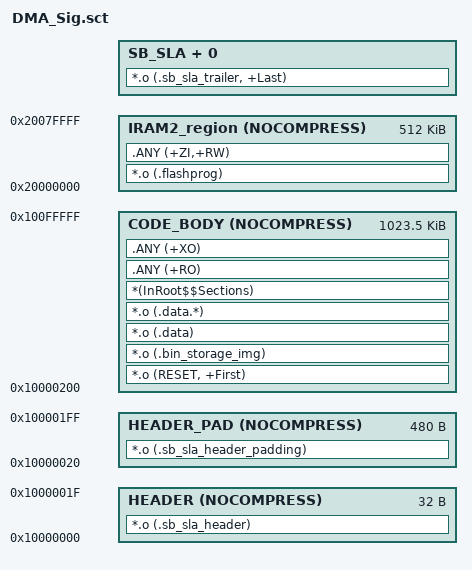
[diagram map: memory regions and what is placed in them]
#! armclang -E --target=arm-arm-none-eabi -mcpu=cortex-m4 -x c


; *************************************************************
; *** Scatter-Loading Description File generated by uVision ***
; *************************************************************

; /*-Memory Regions-*/
#define ROM_start         0x00000000
#define ROM_size          0x00020000
#define FLASH_start__     0x10000000
#define FLASH_size__      0x00100000
#define HEADER_start__    0x10000000
#define HEADER_size__     0x00000020
#define HEADERpad_start__ 0x10000020
#define HEADERpad_size__  0x000001E0
#define CODE_start__      0x10000200
#define CODE_size__       0x000FFE00
#define SPIX_start__      0x08000000
#define SPIX_size__       0x05A12000
#define IRAM_start__      0x20000000
#define IRAM_size__       0x00080000  


LR_IROM1 FLASH_start__ FLASH_size__ { ; load region size_region

	HEADER HEADER_start__  NOCOMPRESS  HEADER_size__ {
		*.o (.sb_sla_header)
	}

	HEADER_PAD HEADERpad_start__  NOCOMPRESS  HEADERpad_size__ {
		*.o (.sb_sla_header_padding)
	}

	CODE_BODY CODE_start__  NOCOMPRESS  CODE_size__ {
		*.o (RESET, +First)
		*.o (.bin_storage_img)
		*.o (.data)
        *.o (.data.*)        
		*(InRoot$$Sections)
		.ANY (+RO)
		.ANY (+XO)
	}

	IRAM2_region IRAM_start__ NOCOMPRESS IRAM_size__  {
		*.o (.flashprog)
		.ANY (+ZI,+RW)
	}
	
}

LR_IROM2 +0 {
 SB_SLA + 0 NOCOMPRESS{
  *.o (.sb_sla_trailer, +Last)
  }
    
}
	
